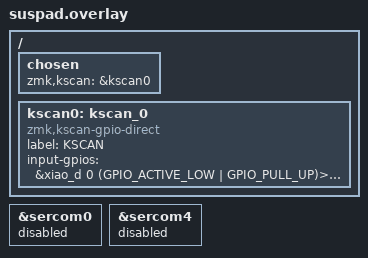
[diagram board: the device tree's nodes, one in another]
/*
 * Copyright (c) 2020 The ZMK Contributors
 *
 * SPDX-License-Identifier: MIT
 */

#include <dt-bindings/zmk/matrix_transform.h>

/ {
    chosen {
        zmk,kscan = &kscan0;
	      /delete-property/ zephyr,console;
      	/delete-property/ zephyr,shell-uart;
    };

	kscan0: kscan_0 {
		compatible = "zmk,kscan-gpio-direct";
		label = "KSCAN";

		input-gpios
			= &xiao_d 0  (GPIO_ACTIVE_LOW | GPIO_PULL_UP)>
			, &xiao_d 1 (GPIO_ACTIVE_LOW | GPIO_PULL_UP)>
			, &xiao_d 2 (GPIO_ACTIVE_LOW | GPIO_PULL_UP)>
			, &xiao_d 3 (GPIO_ACTIVE_LOW | GPIO_PULL_UP)>
			, &xiao_d 4 (GPIO_ACTIVE_LOW | GPIO_PULL_UP)>
			, &xiao_d 5 (GPIO_ACTIVE_LOW | GPIO_PULL_UP)>
			, &xiao_d 6 (GPIO_ACTIVE_LOW | GPIO_PULL_UP)>
			, &xiao_d 7 (GPIO_ACTIVE_LOW | GPIO_PULL_UP)>
			;
	};
};

&sercom0 { status = "disabled"; };
&sercom4 { status = "disabled"; };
